# nrf54lm20a_enga_application register map
Vendor: Nordic Semiconductor; Series: nrf54l; File version: 1
CPU: CM33 r0p4, little endian, MPU, FPU, 3 interrupt priority bits, 270 interrupts, 4 SAU regions
Registers are 32-bit, read-write, reset 0x0 unless marked. A register's access mark holds for its fields unless they carry their own. Offsets are from the block's base; [hi:lo] are bit positions; lines under a group give offsets from that group; {n}, {i} and the like mark numbered series; 'fields as' and 'values as' point back to an identical list.

## GLOBAL_USBHS_NS — USBHS 0
Base 0x4005A000
Same registers: GLOBAL_USBHS_S 0x5005A000
0x00 TASKS_START wo — Start the USB peripheral.
  [0] TASKS_START
    1=Trigger task
0x04 TASKS_STOP wo — Stop the USB peripheral
  [0] TASKS_STOP
    1=Trigger task
0x100 EVENTS_OTGSESSVLD0 — This event triggers when the state of the signal OTGSESSVLD0 changes
  [0] EVENTS_OTGSESSVLD0
    0=NotGenerated (Event not generated); 1=Generated (Event generated)
0x104 EVENTS_CHGDET — This event triggers when the state of the signal CHGDET changes
  [0] EVENTS_CHGDET
    values as EVENTS_OTGSESSVLD0.EVENTS_OTGSESSVLD0
0x108 EVENTS_FSVPLUS — This event triggers when the state of the signal FSVPLUS changes
  [0] EVENTS_FSVPLUS
    values as EVENTS_OTGSESSVLD0.EVENTS_OTGSESSVLD0
0x10C EVENTS_FSVMINUS — This event triggers when the state of the signal FSVMINUS changes
  [0] EVENTS_FSVMINUS
    values as EVENTS_OTGSESSVLD0.EVENTS_OTGSESSVLD0
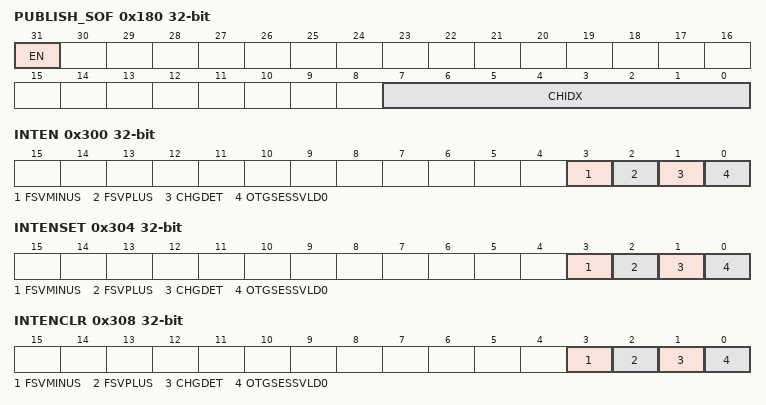
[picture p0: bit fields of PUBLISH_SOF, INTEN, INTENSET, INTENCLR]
0x180 PUBLISH_SOF — Publish configuration for SOF event.
  [31] EN — Enable publishing of SOF event
    0=Disabled (Disable publishing); 1=Enabled (Enable publishing)
  [7:0] CHIDX — DPPI channel to publish to
0x300 INTEN — Enable or disable interrupt
  [all] fields
    0=Disabled; 1=Enabled
  [3] FSVMINUS — Enable or disable interrupt for event FSVMINUS
  [2] FSVPLUS — Enable or disable interrupt for event FSVPLUS
  [1] CHGDET — Enable or disable interrupt for event CHGDET
  [0] OTGSESSVLD0 — Enable or disable interrupt for event OTGSESSVLD0
0x304 INTENSET — Enable interrupt
  [all] fields
    on read: 0=Disabled (Read: Disabled); 1=Enabled (Read: Enabled) | on write: 1=Set (Enable)
  [3] FSVMINUS — Write '1' to enable interrupt for event FSVMINUS
  [2] FSVPLUS — Write '1' to enable interrupt for event FSVPLUS
  [1] CHGDET — Write '1' to enable interrupt for event CHGDET
  [0] OTGSESSVLD0 — Write '1' to enable interrupt for event OTGSESSVLD0
0x308 INTENCLR — Disable interrupt
  [all] fields
    on read: 0=Disabled (Read: Disabled); 1=Enabled (Read: Enabled) | on write: 1=Clear (Disable)
  [3] FSVMINUS — Write '1' to disable interrupt for event FSVMINUS
  [2] FSVPLUS — Write '1' to disable interrupt for event FSVPLUS
  [1] CHGDET — Write '1' to disable interrupt for event CHGDET
  [0] OTGSESSVLD0 — Write '1' to disable interrupt for event OTGSESSVLD0
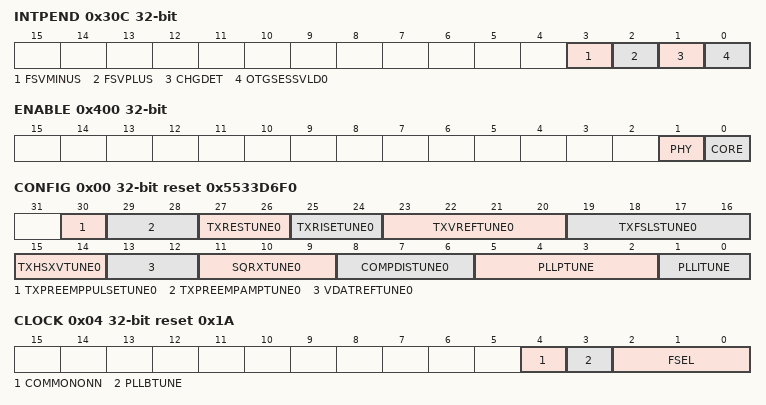
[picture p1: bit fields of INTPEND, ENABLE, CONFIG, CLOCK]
0x30C INTPEND ro — Pending interrupts
  [all] fields
    on read: 0=NotPending (Read: Not pending); 1=Pending (Read: Pending)
  [3] FSVMINUS — Read pending status of interrupt for event FSVMINUS
  [2] FSVPLUS — Read pending status of interrupt for event FSVPLUS
  [1] CHGDET — Read pending status of interrupt for event CHGDET
  [0] OTGSESSVLD0 — Read pending status of interrupt for event OTGSESSVLD0
0x400 ENABLE — Enable USB peripheral.
  [1] PHY — Enable USB PHY
    0=Disabled (USB PHY disabled.); 1=Enabled (USB PHY enabled.)
  [0] CORE — Enable USB Controller
    0=Disabled (USB Controller disabled.); 1=Enabled (USB Controller enabled.)
0x404 DEBOUNCEFILTER — Configuration of debounce filters for avalid, bvalid, vbusvalid, sessend and iddig signals
  [0] BYPASS — Bypass debounce filters
    0=Disabled (Bypass disabled.); 1=Enabled (Bypass enabled.)
0x440 PHY group — Unspecified
  0x00 CONFIG reset 0x5533D6F0 — USB PHY parameter overrides
    [30] TXPREEMPPULSETUNE0 — HS Transmitter Pre-Emphasis Duration Control
    [29:28] TXPREEMPAMPTUNE0 — HS Transmitter Pre-Emphasis Current Control
    [27:26] TXRESTUNE0 — USB Source Impedance Adjustment
    [25:24] TXRISETUNE0 — HS Transmitter Rise/Fall Time Adjustment
    [23:20] TXVREFTUNE0 — HS DC Voltage Level Adjustment
    [19:16] TXFSLSTUNE0 — FS/LS Source Impedance Adjustment
    [15:14] TXHSXVTUNE0 — Transmitter High-Speed Crossover Adjustment
    [13:12] VDATREFTUNE0 — Data Detect Voltage Adjustment
    [11:9] SQRXTUNE0 — Squelch Threshold Adjustment
    [8:6] COMPDISTUNE0 — Disconnect Threshold Adjustment
    [5:2] PLLPTUNE — PLL Proportional Path Tune
    [1:0] PLLITUNE — PLL Integral Path Tune
  0x04 CLOCK reset 0x1A — USB PHY clock configurations
    [4] COMMONONN — Common block power down control
      0=POWERED (The REFCLOCK_LOGIC,bias and PLL blocks are powered in sleep or suspend mode.); 1=SUSPEND (The REFCLOCK_LOGIC, bias and PLL blocks are powered down in suspend mode and bias and PLL blocks are powered down in sleep mode.)
    [3] PLLBTUNE — PLL bandwidth adjustment
      0=Disabled (PLL bandwidth adjustment disabled.); 1=Enabled (PLL bandwidth adjustment enabled.)
    [2:0] FSEL — Select reference clock frequency
      0=Clock19200KHz (Reference clock is 19.2MHz.); 1=Clock20000KHz (Reference clock is 20MHz.); 2=Clock24000KHz (Reference clock is 24MHz.); 7=Clock50000KHz (Reference clock is 50MHz.)
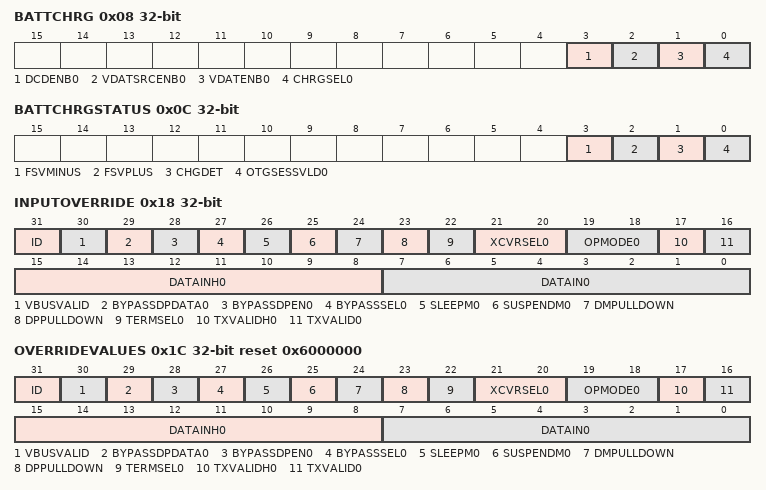
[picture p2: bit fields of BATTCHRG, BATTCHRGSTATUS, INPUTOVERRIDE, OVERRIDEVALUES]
  0x08 BATTCHRG — Battery Charging Configuration
    [3] DCDENB0 — Enhanced Data Contact Detection Enable
      0=Disabled (IDP_SRC current is disabled); 1=Enabled (IDP_SRC current is sourced onto DP0)
    [2] VDATSRCENB0 — Battery Charging Source Select
      0=Disabled (Data source voltage (VDAT_SRC) is disabled); 1=Enabled (Data source voltage (VDAT_SRC) is enabled)
    [1] VDATENB0 — Attach/Connect Detection Enable
      0=Disabled (Data detect voltage (CHG_DET) is disabled); 1=Enabled (Data detect voltage (CHG_DET) is enabled)
    [0] CHRGSEL0 — Battery charging source select
      0=SourceDP0SinkDM0 (Data source voltage (VDAT_SRC) is sourced onto DP0 and sunk from DM0); 1=SourceDM0SinkDP0 (Data source voltage (VDAT_SRC) is sourced onto DM0 and sunk from DP0)
  0x0C BATTCHRGSTATUS ro — Battery charger input signals
    [3] FSVMINUS, [2] FSVPLUS, [1] CHGDET, [0] OTGSESSVLD0
  0x10 VREGBYPASS — Vreg18 bypass control
    [0] EN — Vreg18 bypass enable
      0=Vreg18Enabled (A 3.3V supply must be provided on VDDH0. Internal 1.8V supply is generated by Vreg18); 1=Vreg18Bypassed (A 1.8V supply must be provided on VDDH0. Vreg18 is bypassed)
  0x14 VREGBYPASSLOCK — Enables the lock for the PHY.VREGBYPASS
    [0] EnableLock — Enables the lock.
      on read: 0=LockDisabled (Read: PHY.VREGBYPASS is not locked.); 1=LockEnabled (Read: PHY.VREGBYPASS is locked.) | on write: 1=EnableLock (Write: Enables the lock (Ignores any other value written).)
  0x18 INPUTOVERRIDE — Enables overriding of individual signals to the PHY, the override values are set in PHY.OVERRIDEVALUES Can be used for PHY Built In Self Test (BIST).
    [31] ID — Overrides OTG ID pin signal
    [30] VBUSVALID
    [29] BYPASSDPDATA0
    [28] BYPASSDPEN0
    [27] BYPASSSEL0
    [26] SLEEPM0
    [25] SUSPENDM0
    [24] DMPULLDOWN
    [23] DPPULLDOWN
    [22] TERMSEL0
    [21:20] XCVRSEL0
      0=Disabled (Overrides are disabled); 3=Enabled (Overrides are enabled)
    [19:18] OPMODE0
      values as XCVRSEL0
    [17] TXVALIDH0
    [16] TXVALID0
    [15:8] DATAINH0
      0=Disabled (Overrides are disabled); 255=Enabled (Overrides are enabled)
    [7:0] DATAIN0
      values as DATAINH0
  0x1C OVERRIDEVALUES reset 0x6000000 — Values that are used to override the input signals to the PHY.
    [31] ID — Overrides OTG ID pin signal
      1=Device (Role is Device); 0=Host (Role is Host.)
    [30] VBUSVALID — Signals to the PHY that VBUS is valid, and enables the pull-up resistor on D+
      1=Valid (VBUS is valid, and the pull up resistor on D+ is enabled); 0=NotValid (VBUS is not valid, and the pull up resistor on D+ is disabled.)
    [29] BYPASSDPDATA0
    [28] BYPASSDPEN0
    [27] BYPASSSEL0
    [26] SLEEPM0
    [25] SUSPENDM0
    [24] DMPULLDOWN — This field controls the pull-down resistor on D-
      1=Enable (The pull-down resistor on D- is enabled); 0=Disable (The pull-down resistor on D- is disabled)
    [23] DPPULLDOWN — This field controls the pull-down resistor on D+
      1=Enable (The pull-down resistor on D+ is enabled); 0=Disable (The pull-down resistor on D+ is disabled)
    [22] TERMSEL0
    [21:20] XCVRSEL0
    [19:18] OPMODE0
    [17] TXVALIDH0
    [16] TXVALID0
    [15:8] DATAINH0
    [7:0] DATAIN0
  0x20 BISTOVERRIDE — This register enables a set of overrides with fixed values in addition to the overrides with selectable values in INPUTOVERRIDES.
    [0] ENABLE
      1=Enable (Unspecified); 0=Disable (Unspecified)
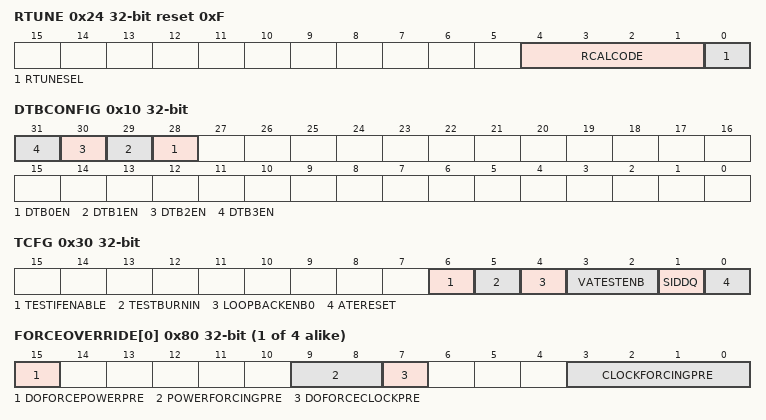
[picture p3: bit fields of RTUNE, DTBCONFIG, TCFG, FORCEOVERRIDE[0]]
  0x24 RTUNE reset 0xF — The RTUNE mode is an alternative method for calibrating the DP and DM 45-Ohm source impedance.
    [4:1] RCALCODE — This signal is used to tune the internal 200 ohm resistor or the USBHS DP and DM high-speed source impedance.
    [0] RTUNESEL — This signal selects the tuning method for the high-speed DP and DM source impedance of the USBHS.
      1=TXRTUNE (The TXRTUNE pin, external resistor REXT, and resulting internal digital calibration code are used for tuning the high-speed source impedance.); 0=RTUNE (The RCALCODE value is used for tuning the high-speed source impedance.)
0x600 DFT group — Unspecified
  0x00 ATB0CONFIG — Analog Test Bus 0 (ATB0) configuration
    [31] EN — Enable ANALOGTEST on the analog test bus
      0=Disabled (Analog test bus is disabled); 1=Enabled (Analog test bus is enabled)
  0x04 ATB1CONFIG — Analog Test Bus 1 (ATB1) configuration
    [31] EN — Enable ANALOGTESTATE on the analog test bus
      values as DFT.ATB0CONFIG.EN
  0x10 DTBCONFIG — Digital Test Bus configuration
    [all] fields
      0=Disabled (Digital test bus is disabled); 1=Enabled (Digital test bus is enabled)
    [n+28] DTB{n}EN (n=0..3) — Enable TESTDATAOUT[{n}] on DTB{n}
  0x30 TCFG — Test mode configuration
    [6] TESTIFENABLE — Enable the test interface.
      0=Disabled (Test interface synchronizer clock disabled.); 1=Enabled (Test interface synchronizer clock enabled.)
    [5] TESTBURNIN — Burn-In Test Enable
      0=Disabled (Burn-in test disabled); 1=Enabled (Burn-in test enabled. Requires 50MHz reference clock on CLKCORE)
    [4] LOOPBACKENB0 — Loopback Test. enables receive and transmit logic concurrently
      0=Disabled (During data transmission, the receive logic is disabled); 1=Enabled (During data transmission, the receive logic is enabled)
    [3:2] VATESTENB — Analog Test Pin Select
      0=Disabled (Analog test voltages cannot be viewed or applied); 1=ID0 (Analog test voltages cannot be viewed or applied on ID0); 2=ANALOGTEST (Analog test voltages cannot be viewed or applied on ANALOGTEST); 3=Unused (Invalid setting)
    [1] SIDDQ — IDDQ Test Enable
      0=Disabled (Analog blocks are powered up); 1=Enabled (Analog blocks are powered down)
    [0] ATERESET — ATE reset input. Disables PHYCLOCK0 and FREECLK
      0=Clockenabled (PHYCLK0 and FREECLK enabled); 1=Clockdisabled (PHYCLK0 and FREECLK disabled)
  0x34 TESTADDR — Test data address
    [3:0] TESTADDR0 — Test Interface Register Address
  0x38 TESTDATAIN — Test data input
    [7:0] TESTDATAIN0 — Test Data Write Bus
  0x3C TESTDATAOUTSEL — Test data out select
    [0] TESTDATAOUTSEL0 — Determines which signals appear on TESDATAOUT
      0=InternalSignal (Mode-defined, internally generated signals are output); 1=TestRegister (Mode-defined test register contents are output)
  0x40 TESTDATAOUT ro — Test data output
    [3:0] TESTDATAOUT0 — Test Data Read Bus
  0x44 TLATCH wo — Test data latch
    [0] TESTCLK0 — PHY uses the positive edge of TESTCLK0 to latch TESTDATAIN[7:0]
0xC00 PCGCS group — Unspecified
  {0x0+4j} PENALTY[{j}] (j=0..1) reset 0xFFFFFFFC — Description collection: Penalty level for power/clock pair n. When FULL_PCP_ZERO feature is not supported, PENALTY[0] address overlaps the PENALTY0 address and register description for PENALTY[0] is not valid.
    [1:0] PENALTY — Penalty level
  0x00 PENALTY0 (alternate view of PENALTY[*]) — Penalty level for power/clock pair 0. The register description is valid only when FULL_PCP_ZERO feature is not supported
    [1:0] PENALTY ro — Penalty level
  {0x80+4j} FORCEOVERRIDE[{j}] (j=0..3) — Description collection: Force override of power/clock pair n.
    [15] DOFORCEPOWERPRE, [9:8] POWERFORCINGPRE, [7] DOFORCECLOCKPRE, [3:0] CLOCKFORCINGPRE
